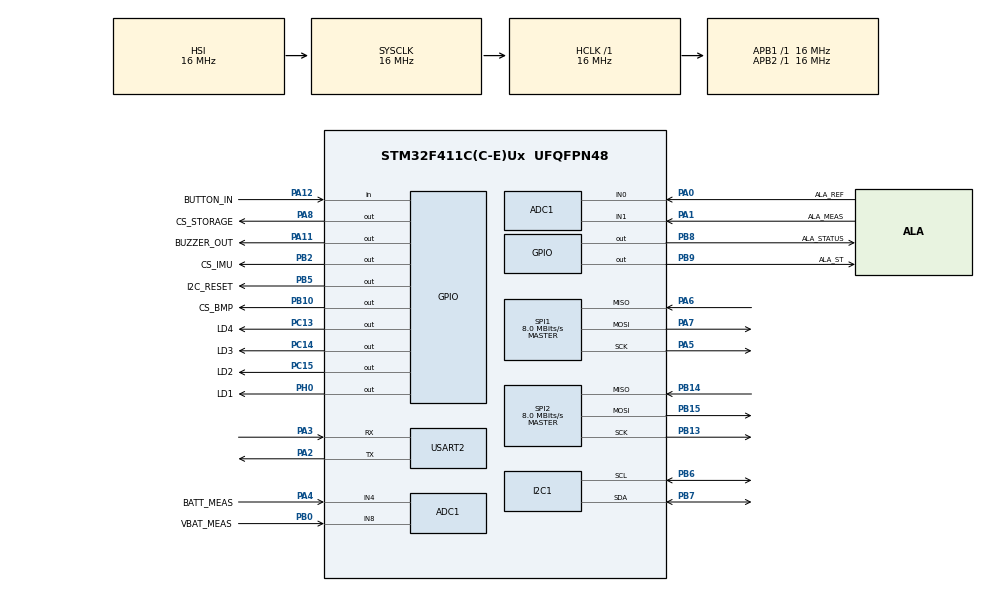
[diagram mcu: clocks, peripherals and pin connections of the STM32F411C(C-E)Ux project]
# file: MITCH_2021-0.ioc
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ADC1.Channel-1\#ChannelRegularConversion=ADC_CHANNEL_4
ADC1.Channel-2\#ChannelInjectedConversion=ADC_CHANNEL_0
ADC1.Channel-3\#ChannelInjectedConversion=ADC_CHANNEL_1
ADC1.Channel-4\#ChannelRegularConversion=ADC_CHANNEL_8
ADC1.ContinuousConvMode=DISABLE
ADC1.DMAContinuousRequests=DISABLE
ADC1.InjNumberOfConversion=2
ADC1.InjectedOffset-2\#ChannelInjectedConversion=0
ADC1.InjectedOffset-3\#ChannelInjectedConversion=0
ADC1.InjectedRank-2\#ChannelInjectedConversion=1
ADC1.InjectedRank-3\#ChannelInjectedConversion=2
ADC1.NbrOfConversion=2
ADC1.NbrOfConversionFlag=1
ADC1.Rank-1\#ChannelRegularConversion=1
ADC1.Rank-4\#ChannelRegularConversion=2
ADC1.SamplingTime-1\#ChannelRegularConversion=ADC_SAMPLETIME_3CYCLES
ADC1.SamplingTime-2\#ChannelInjectedConversion=ADC_SAMPLETIME_3CYCLES
ADC1.SamplingTime-3\#ChannelInjectedConversion=ADC_SAMPLETIME_3CYCLES
ADC1.SamplingTime-4\#ChannelRegularConversion=ADC_SAMPLETIME_3CYCLES
ADC1.ScanConvMode=ENABLE
ADC1.master=1
FREERTOS.INCLUDE_vTaskDelayUntil=1
FREERTOS.Tasks01=Acquisition,3,128,StartAcquisition,Default,NULL,Static,AcquisitionBuffer,AcquisitionControlBlock;Processing,0,128,StartProcessing,Default,NULL,Static,ProcessingBuffer,ProcessingControlBlock
Mcu.Family=STM32F4
Mcu.Name=STM32F411C(C-E)Ux
Mcu.Package=UFQFPN48
NVIC.PriorityGroup=NVIC_PRIORITYGROUP_4
NVIC.USART2_IRQn=true\:5\:0\:false\:false\:true\:true\:true\:true
PA0-WKUP.GPIO_Label=ALA_REF
PA0-WKUP.Signal=ADCx_IN0
PA1.GPIO_Label=ALA_MEAS
PA1.Signal=ADCx_IN1
PA11.GPIO_Label=BUZZER_OUT
PA11.Signal=GPIO_Output
PA12.GPIO_Label=BUTTON_IN
PA12.Signal=GPIO_Input
PA13.Mode=Serial_Wire
PA13.Signal=SYS_JTMS-SWDIO
PA14.Mode=Serial_Wire
PA14.Signal=SYS_JTCK-SWCLK
PA2.Mode=Asynchronous
PA2.Signal=USART2_TX
PA3.Mode=Asynchronous
PA3.Signal=USART2_RX
PA4.GPIO_Label=BATT_MEAS
PA4.Signal=ADCx_IN4
PA5.Mode=Full_Duplex_Master
PA5.Signal=SPI1_SCK
PA6.Mode=Full_Duplex_Master
PA6.Signal=SPI1_MISO
PA7.Mode=Full_Duplex_Master
PA7.Signal=SPI1_MOSI
PA8.GPIO_Label=CS_STORAGE
PA8.Signal=GPIO_Output
PB0.GPIO_Label=VBAT_MEAS
PB0.Signal=ADCx_IN8
PB10.GPIO_Label=CS_BMP
PB10.Signal=GPIO_Output
PB13.Mode=Full_Duplex_Master
PB13.Signal=SPI2_SCK
PB14.Mode=Full_Duplex_Master
PB14.Signal=SPI2_MISO
PB15.Mode=Full_Duplex_Master
PB15.Signal=SPI2_MOSI
PB2.GPIO_Label=CS_IMU
PB2.Signal=GPIO_Output
PB3.Signal=SYS_JTDO-SWO
PB5.GPIO_Label=I2C_RESET
PB5.Signal=GPIO_Output
PB6.Mode=I2C
PB6.Signal=I2C1_SCL
PB7.Mode=I2C
PB7.Signal=I2C1_SDA
PB8.GPIO_Label=ALA_STATUS
PB8.Signal=GPIO_Output
PB9.GPIO_Label=ALA_ST
PB9.Signal=GPIO_Output
PC13-ANTI_TAMP.GPIO_Label=LD4
PC13-ANTI_TAMP.Signal=GPIO_Output
PC14-OSC32_IN.GPIO_Label=LD3
PC14-OSC32_IN.Signal=GPIO_Output
PC15-OSC32_OUT.GPIO_Label=LD2
PC15-OSC32_OUT.Signal=GPIO_Output
PH0\ -\ OSC_IN.GPIO_Label=LD1
PH0\ -\ OSC_IN.Signal=GPIO_Output
ProjectManager.HeapSize=0x200
ProjectManager.StackSize=0x400
ProjectManager.TargetToolchain=STM32CubeIDE
RCC.AHBFreq_Value=16000000
RCC.APB1Freq_Value=16000000
RCC.APB2Freq_Value=16000000
RCC.CortexFreq_Value=16000000
RCC.HSE_VALUE=25000000
RCC.HSI_VALUE=16000000
RCC.LSE_VALUE=32768
RCC.SYSCLKFreq_VALUE=16000000
RCC.VCOOutputFreq_Value=192000000
SH.ADCx_IN0.0=ADC1_IN0,IN0
SH.ADCx_IN1.0=ADC1_IN1,IN1
SH.ADCx_IN4.0=ADC1_IN4,IN4
SH.ADCx_IN8.0=ADC1_IN8,IN8
SPI1.CalculateBaudRate=8.0 MBits/s
SPI1.Direction=SPI_DIRECTION_2LINES
SPI1.Mode=SPI_MODE_MASTER
SPI1.VirtualType=VM_MASTER
SPI2.CalculateBaudRate=8.0 MBits/s
SPI2.Direction=SPI_DIRECTION_2LINES
SPI2.Mode=SPI_MODE_MASTER
SPI2.VirtualType=VM_MASTER
USART2.VirtualMode=VM_ASYNC
VP_ADC1_Vbat_Input.Mode=IN-Vbat
VP_FREERTOS_VS_CMSIS_V1.Mode=CMSIS_V1
board=custom

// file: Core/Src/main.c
/* USER CODE BEGIN Header */
/**
  ******************************************************************************
  * @file           : main.c
  * @brief          : Main program body
  ******************************************************************************
  * @attention
  *
  * <h2><center>&copy; Copyright (c) 2021 STMicroelectronics.
  * All rights reserved.</center></h2>
  *
  * This software component is licensed by ST under Ultimate Liberty license
  * SLA0044, the "License"; You may not use this file except in compliance with
  * the License. You may obtain a copy of the License at:
  *                             www.st.com/SLA0044
  *
  ******************************************************************************
  */
/* USER CODE END Header */
#include "main.h"
#include "cmsis_os.h"

/* USER CODE BEGIN Includes */
#include "generic_interface.h"
#include "MT3339.h"
#include "MS5607.h"
/* USER CODE END Includes */

ADC_HandleTypeDef hadc1;

I2C_HandleTypeDef hi2c1;

SPI_HandleTypeDef hspi1;
SPI_HandleTypeDef hspi2;

UART_HandleTypeDef huart2;

osThreadId AcquisitionHandle;
uint32_t AcquisitionBuffer[ 128 ];
osStaticThreadDef_t AcquisitionControlBlock;
osThreadId ProcessingHandle;
uint32_t ProcessingBuffer[ 128 ];
osStaticThreadDef_t ProcessingControlBlock;
/* USER CODE BEGIN PV */

/** Device Declarations **/
//volatile genericDevice_t bmp;

/** Interface Struct Initializations **/
//volatile bmpData_t bmpData = {0};

/* USER CODE END PV */

void SystemClock_Config(void);
static void MX_GPIO_Init(void);
static void MX_SPI1_Init(void);
static void MX_SPI2_Init(void);
static void MX_USART2_UART_Init(void);
static void MX_ADC1_Init(void);
static void MX_I2C1_Init(void);
void StartAcquisition(void const * argument);
void StartProcessing(void const * argument);

int main(void)
{

  /* MCU Configuration--------------------------------------------------------*/

  /* Reset of all peripherals, Initializes the Flash interface and the Systick. */
  HAL_Init();

  /* Configure the system clock */
  SystemClock_Config();

  /* Initialize all configured peripherals */
  MX_GPIO_Init();
  MX_SPI1_Init();
  MX_SPI2_Init();
  MX_USART2_UART_Init();
  MX_ADC1_Init();
  MX_I2C1_Init();

  /* Create the thread(s) */
  /* definition and creation of Acquisition */
  osThreadStaticDef(Acquisition, StartAcquisition, osPriorityRealtime, 0, 128, AcquisitionBuffer, &AcquisitionControlBlock);
  AcquisitionHandle = osThreadCreate(osThread(Acquisition), NULL);

  /* definition and creation of Processing */
  osThreadStaticDef(Processing, StartProcessing, osPriorityNormal, 0, 128, ProcessingBuffer, &ProcessingControlBlock);
  ProcessingHandle = osThreadCreate(osThread(Processing), NULL);

  /* Start scheduler */
  osKernelStart();

  /* We should never get here as control is now taken by the scheduler */
  /* Infinite loop */
  while (1)
  {

  }
}

void SystemClock_Config(void)
{
  RCC_OscInitTypeDef RCC_OscInitStruct = {0};
  RCC_ClkInitTypeDef RCC_ClkInitStruct = {0};

  /** Configure the main internal regulator output voltage
  */
  __HAL_RCC_PWR_CLK_ENABLE();
  __HAL_PWR_VOLTAGESCALING_CONFIG(PWR_REGULATOR_VOLTAGE_SCALE1);
  /** Initializes the RCC Oscillators according to the specified parameters
  * in the RCC_OscInitTypeDef structure.
  */
  RCC_OscInitStruct.OscillatorType = RCC_OSCILLATORTYPE_HSI;
  RCC_OscInitStruct.HSIState = RCC_HSI_ON;
  RCC_OscInitStruct.HSICalibrationValue = RCC_HSICALIBRATION_DEFAULT;
  RCC_OscInitStruct.PLL.PLLState = RCC_PLL_NONE;
  if (HAL_RCC_OscConfig(&RCC_OscInitStruct) != HAL_OK)
  {
    Error_Handler();
  }
  /** Initializes the CPU, AHB and APB buses clocks
  */
  RCC_ClkInitStruct.ClockType = RCC_CLOCKTYPE_HCLK|RCC_CLOCKTYPE_SYSCLK
                              |RCC_CLOCKTYPE_PCLK1|RCC_CLOCKTYPE_PCLK2;
  RCC_ClkInitStruct.SYSCLKSource = RCC_SYSCLKSOURCE_HSI;
  RCC_ClkInitStruct.AHBCLKDivider = RCC_SYSCLK_DIV1;
  RCC_ClkInitStruct.APB1CLKDivider = RCC_HCLK_DIV1;
  RCC_ClkInitStruct.APB2CLKDivider = RCC_HCLK_DIV1;

  if (HAL_RCC_ClockConfig(&RCC_ClkInitStruct, FLASH_LATENCY_0) != HAL_OK)
  {
    Error_Handler();
  }
}

static void MX_ADC1_Init(void)
{

  ADC_ChannelConfTypeDef sConfig = {0};
  ADC_InjectionConfTypeDef sConfigInjected = {0};

  /** Configure the global features of the ADC (Clock, Resolution, Data Alignment and number of conversion)
  */
  hadc1.Instance = ADC1;
  hadc1.Init.ClockPrescaler = ADC_CLOCK_SYNC_PCLK_DIV2;
  hadc1.Init.Resolution = ADC_RESOLUTION_12B;
  hadc1.Init.ScanConvMode = ENABLE;
  hadc1.Init.ContinuousConvMode = DISABLE;
  hadc1.Init.DiscontinuousConvMode = DISABLE;
  hadc1.Init.ExternalTrigConvEdge = ADC_EXTERNALTRIGCONVEDGE_NONE;
  hadc1.Init.ExternalTrigConv = ADC_SOFTWARE_START;
  hadc1.Init.DataAlign = ADC_DATAALIGN_RIGHT;
  hadc1.Init.NbrOfConversion = 2;
  hadc1.Init.DMAContinuousRequests = DISABLE;
  hadc1.Init.EOCSelection = ADC_EOC_SINGLE_CONV;
  if (HAL_ADC_Init(&hadc1) != HAL_OK)
  {
    Error_Handler();
  }
  /** Configure for the selected ADC regular channel its corresponding rank in the sequencer and its sample time.
  */
  sConfig.Channel = ADC_CHANNEL_4;
  sConfig.Rank = 1;
  sConfig.SamplingTime = ADC_SAMPLETIME_3CYCLES;
  if (HAL_ADC_ConfigChannel(&hadc1, &sConfig) != HAL_OK)
  {
    Error_Handler();
  }
  /** Configure for the selected ADC regular channel its corresponding rank in the sequencer and its sample time.
  */
  sConfig.Channel = ADC_CHANNEL_8;
  sConfig.Rank = 2;
  if (HAL_ADC_ConfigChannel(&hadc1, &sConfig) != HAL_OK)
  {
    Error_Handler();
  }
  /** Configures for the selected ADC injected channel its corresponding rank in the sequencer and its sample time
  */
  sConfigInjected.InjectedChannel = ADC_CHANNEL_0;
  sConfigInjected.InjectedRank = 1;
  sConfigInjected.InjectedNbrOfConversion = 2;
  sConfigInjected.InjectedSamplingTime = ADC_SAMPLETIME_3CYCLES;
  sConfigInjected.ExternalTrigInjecConvEdge = ADC_EXTERNALTRIGINJECCONVEDGE_NONE;
  sConfigInjected.ExternalTrigInjecConv = ADC_INJECTED_SOFTWARE_START;
  sConfigInjected.AutoInjectedConv = DISABLE;
  sConfigInjected.InjectedDiscontinuousConvMode = DISABLE;
  sConfigInjected.InjectedOffset = 0;
  if (HAL_ADCEx_InjectedConfigChannel(&hadc1, &sConfigInjected) != HAL_OK)
  {
    Error_Handler();
  }
  /** Configures for the selected ADC injected channel its corresponding rank in the sequencer and its sample time
  */
  sConfigInjected.InjectedChannel = ADC_CHANNEL_1;
  sConfigInjected.InjectedRank = 2;
  if (HAL_ADCEx_InjectedConfigChannel(&hadc1, &sConfigInjected) != HAL_OK)
  {
    Error_Handler();
  }

}

static void MX_I2C1_Init(void)
{

  hi2c1.Instance = I2C1;
  hi2c1.Init.ClockSpeed = 100000;
  hi2c1.Init.DutyCycle = I2C_DUTYCYCLE_2;
  hi2c1.Init.OwnAddress1 = 0;
  hi2c1.Init.AddressingMode = I2C_ADDRESSINGMODE_7BIT;
  hi2c1.Init.DualAddressMode = I2C_DUALADDRESS_DISABLE;
  hi2c1.Init.OwnAddress2 = 0;
  hi2c1.Init.GeneralCallMode = I2C_GENERALCALL_DISABLE;
  hi2c1.Init.NoStretchMode = I2C_NOSTRETCH_DISABLE;
  if (HAL_I2C_Init(&hi2c1) != HAL_OK)
  {
    Error_Handler();
  }

}

static void MX_SPI1_Init(void)
{

  /* SPI1 parameter configuration*/
  hspi1.Instance = SPI1;
  hspi1.Init.Mode = SPI_MODE_MASTER;
  hspi1.Init.Direction = SPI_DIRECTION_2LINES;
  hspi1.Init.DataSize = SPI_DATASIZE_8BIT;
  hspi1.Init.CLKPolarity = SPI_POLARITY_LOW;
  hspi1.Init.CLKPhase = SPI_PHASE_1EDGE;
  hspi1.Init.NSS = SPI_NSS_SOFT;
  hspi1.Init.BaudRatePrescaler = SPI_BAUDRATEPRESCALER_2;
  hspi1.Init.FirstBit = SPI_FIRSTBIT_MSB;
  hspi1.Init.TIMode = SPI_TIMODE_DISABLE;
  hspi1.Init.CRCCalculation = SPI_CRCCALCULATION_DISABLE;
  hspi1.Init.CRCPolynomial = 10;
  if (HAL_SPI_Init(&hspi1) != HAL_OK)
  {
    Error_Handler();
  }

}

static void MX_SPI2_Init(void)
{

  /* SPI2 parameter configuration*/
  hspi2.Instance = SPI2;
  hspi2.Init.Mode = SPI_MODE_MASTER;
  hspi2.Init.Direction = SPI_DIRECTION_2LINES;
  hspi2.Init.DataSize = SPI_DATASIZE_8BIT;
  hspi2.Init.CLKPolarity = SPI_POLARITY_LOW;
  hspi2.Init.CLKPhase = SPI_PHASE_1EDGE;
  hspi2.Init.NSS = SPI_NSS_SOFT;
  hspi2.Init.BaudRatePrescaler = SPI_BAUDRATEPRESCALER_2;
  hspi2.Init.FirstBit = SPI_FIRSTBIT_MSB;
  hspi2.Init.TIMode = SPI_TIMODE_DISABLE;
  hspi2.Init.CRCCalculation = SPI_CRCCALCULATION_DISABLE;
  hspi2.Init.CRCPolynomial = 10;
  if (HAL_SPI_Init(&hspi2) != HAL_OK)
  {
    Error_Handler();
  }

}

static void MX_USART2_UART_Init(void)
{

  huart2.Instance = USART2;
  huart2.Init.BaudRate = 115200;
  huart2.Init.WordLength = UART_WORDLENGTH_8B;
  huart2.Init.StopBits = UART_STOPBITS_1;
  huart2.Init.Parity = UART_PARITY_NONE;
  huart2.Init.Mode = UART_MODE_TX_RX;
  huart2.Init.HwFlowCtl = UART_HWCONTROL_NONE;
  huart2.Init.OverSampling = UART_OVERSAMPLING_16;
  if (HAL_UART_Init(&huart2) != HAL_OK)
  {
    Error_Handler();
  }

}

static void MX_GPIO_Init(void)
{
  GPIO_InitTypeDef GPIO_InitStruct = {0};

  /* GPIO Ports Clock Enable */
  __HAL_RCC_GPIOC_CLK_ENABLE();
  __HAL_RCC_GPIOH_CLK_ENABLE();
  __HAL_RCC_GPIOA_CLK_ENABLE();
  __HAL_RCC_GPIOB_CLK_ENABLE();

  /*Configure GPIO pin Output Level */
  HAL_GPIO_WritePin(GPIOC, LD4_Pin|LD3_Pin|LD2_Pin, GPIO_PIN_RESET);

  /*Configure GPIO pin Output Level */
  HAL_GPIO_WritePin(LD1_GPIO_Port, LD1_Pin, GPIO_PIN_RESET);

  /*Configure GPIO pin Output Level */
  HAL_GPIO_WritePin(GPIOB, CS_IMU_Pin|CS_BMP_Pin|I2C_RESET_Pin|ALA_STATUS_Pin
                          |ALA_ST_Pin, GPIO_PIN_RESET);

  /*Configure GPIO pin Output Level */
  HAL_GPIO_WritePin(GPIOA, CS_STORAGE_Pin|BUZZER_OUT_Pin, GPIO_PIN_RESET);

  /*Configure GPIO pins : LD4_Pin LD3_Pin LD2_Pin */
  GPIO_InitStruct.Pin = LD4_Pin|LD3_Pin|LD2_Pin;
  GPIO_InitStruct.Mode = GPIO_MODE_OUTPUT_PP;
  GPIO_InitStruct.Pull = GPIO_NOPULL;
  GPIO_InitStruct.Speed = GPIO_SPEED_FREQ_LOW;
  HAL_GPIO_Init(GPIOC, &GPIO_InitStruct);

  /*Configure GPIO pin : LD1_Pin */
  GPIO_InitStruct.Pin = LD1_Pin;
  GPIO_InitStruct.Mode = GPIO_MODE_OUTPUT_PP;
  GPIO_InitStruct.Pull = GPIO_NOPULL;
  GPIO_InitStruct.Speed = GPIO_SPEED_FREQ_LOW;
  HAL_GPIO_Init(LD1_GPIO_Port, &GPIO_InitStruct);

  /*Configure GPIO pins : CS_IMU_Pin CS_BMP_Pin I2C_RESET_Pin ALA_STATUS_Pin
                           ALA_ST_Pin */
  GPIO_InitStruct.Pin = CS_IMU_Pin|CS_BMP_Pin|I2C_RESET_Pin|ALA_STATUS_Pin
                          |ALA_ST_Pin;
  GPIO_InitStruct.Mode = GPIO_MODE_OUTPUT_PP;
  GPIO_InitStruct.Pull = GPIO_NOPULL;
  GPIO_InitStruct.Speed = GPIO_SPEED_FREQ_LOW;
  HAL_GPIO_Init(GPIOB, &GPIO_InitStruct);

  /*Configure GPIO pins : CS_STORAGE_Pin BUZZER_OUT_Pin */
  GPIO_InitStruct.Pin = CS_STORAGE_Pin|BUZZER_OUT_Pin;
  GPIO_InitStruct.Mode = GPIO_MODE_OUTPUT_PP;
  GPIO_InitStruct.Pull = GPIO_NOPULL;
  GPIO_InitStruct.Speed = GPIO_SPEED_FREQ_LOW;
  HAL_GPIO_Init(GPIOA, &GPIO_InitStruct);

  /*Configure GPIO pin : BUTTON_IN_Pin */
  GPIO_InitStruct.Pin = BUTTON_IN_Pin;
  GPIO_InitStruct.Mode = GPIO_MODE_INPUT;
  GPIO_InitStruct.Pull = GPIO_NOPULL;
  HAL_GPIO_Init(BUTTON_IN_GPIO_Port, &GPIO_InitStruct);

}

void StartAcquisition(void const * argument)
{
  for(;;)
  {
    osDelay(1);
  }
}

void StartProcessing(void const * argument)
{
  for(;;)
  {
    osDelay(1);
  }
}

void Error_Handler(void)
{
  __disable_irq();
  while (1)
  {
  }
}

/************************ (C) COPYRIGHT STMicroelectronics *****END OF FILE****/
